# AT32F403xx register map
Vendor: Keil; Series: AT32F403; File version: 1.0
CPU: CM4 r0p1, little endian, no MPU, FPU, 4 interrupt priority bits
Registers are 32-bit, read-write, reset 0x0 unless marked. A register's access mark holds for its fields unless they carry their own. Offsets are from the block's base; [hi:lo] are bit positions; {n}, {i} and the like mark numbered series; 'fields as' and 'values as' point back to an identical list.

## AFIO — Alternate function I/O
Base 0x40010000
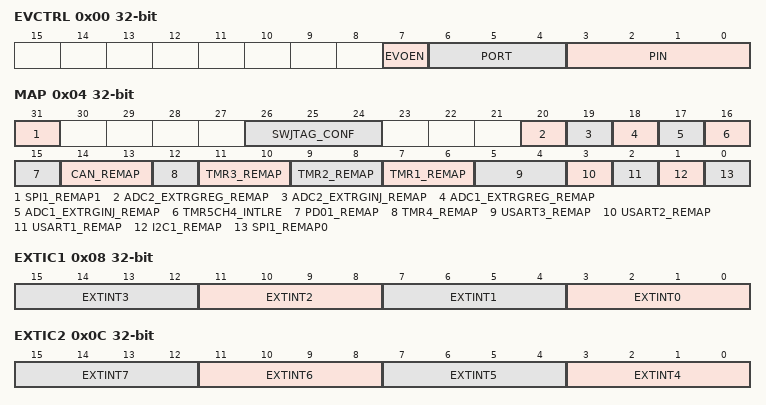
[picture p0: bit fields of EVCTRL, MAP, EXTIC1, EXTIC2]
0x00 EVCTRL — Event Control Register (AFIO_EVCTRL)
  [7] EVOEN — Event Output Enable
  [6:4] PORT — Port selection
  [3:0] PIN — Pin selection
0x04 MAP — AF remap and debug I/O configuration register (AFIO_MAP)
  [31] SPI1_REMAP1 — SPI1 remapping bit1
  [26:24] SWJTAG_CONF — Serial wire JTAG configuration
  [20] ADC2_EXTRGREG_REMAP — ADC 2 external trigger regular conversion remapping
  [19] ADC2_EXTRGINJ_REMAP — ADC 2 external trigger injected conversion remapping
  [18] ADC1_EXTRGREG_REMAP — ADC 1 external trigger regular conversion remapping
  [17] ADC1_EXTRGINJ_REMAP — ADC 1 External trigger injected conversion remapping
  [16] TMR5CH4_INTLRE — Set and cleared by software
  [15] PD01_REMAP — Port D0/Port D1 mapping on OSCIN/OSCOUT
  [14:13] CAN_REMAP — CAN1 remapping
  [12] TMR4_REMAP — TIM4 remapping
  [11:10] TMR3_REMAP — TIM3 remapping
  [9:8] TMR2_REMAP — TIM2 remapping
  [7:6] TMR1_REMAP — TIM1 remapping
  [5:4] USART3_REMAP — USART3 remapping
  [3] USART2_REMAP — USART2 remapping
  [2] USART1_REMAP — USART1 remapping
  [1] I2C1_REMAP — I2C1 remapping
  [0] SPI1_REMAP0 — SPI1 remapping bit0
0x08 EXTIC1 — External interrupt configuration register 1 (AFIO_EXTIC1)
  [4n+3:4n] EXTINT{n} (n=0..3) — EXTI{n} configuration
0x0C EXTIC2 — External interrupt configuration register 2 (AFIO_EXTIC2)
  [4n-13:4n-16] EXTINT{n} (n=4..7) — EXTI{n} configuration
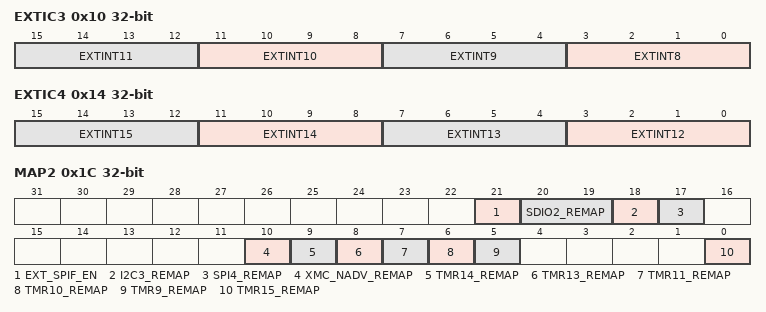
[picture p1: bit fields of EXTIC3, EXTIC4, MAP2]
0x10 EXTIC3 — External interrupt configuration register 3 (AFIO_EXTIC3)
  [4n-29:4n-32] EXTINT{n} (n=8..11) — EXTI{n} configuration
0x14 EXTIC4 — External interrupt configuration register 4 (AFIO_EXTIC4)
  [4n-45:4n-48] EXTINT{n} (n=12..15) — EXTI{n} configuration
0x1C MAP2 — AF remap and debug I/O configuration register
  [21] EXT_SPIF_EN — Enable ExtSPIFlash
  [20:19] SDIO2_REMAP — SDIO2 remapping
  [18] I2C3_REMAP — I2C3 remapping
  [17] SPI4_REMAP — SPI4 remapping
  [10] XMC_NADV_REMAP — NADV connect/disconnect
  [9] TMR14_REMAP — TIM14 remapping
  [8] TMR13_REMAP — TIM13 remapping
  [7] TMR11_REMAP — TIM11 remapping
  [6] TMR10_REMAP — TIM10 remapping
  [5] TMR9_REMAP — TIM9 remapping
  [0] TMR15_REMAP — TIM15 remapping

## EXTI
Base 0x40010400
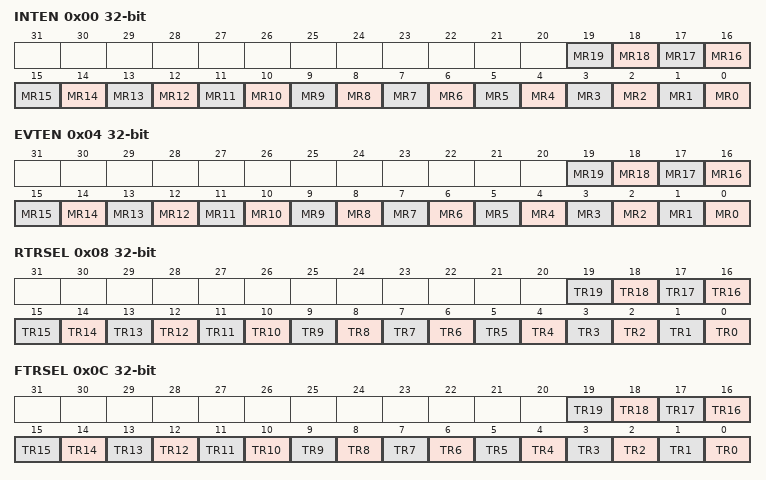
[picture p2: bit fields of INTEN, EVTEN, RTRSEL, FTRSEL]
0x00 INTEN — Interrupt mask register (EXTI_INTEN)
  [n] MR{n} (n=0..19) — Interrupt Mask on line {n}
0x04 EVTEN — Event mask register (EXTI_EVTEN)
  [n] MR{n} (n=0..19) — Event Mask on line {n}
0x08 RTRSEL — Rising Trigger selection register (EXTI_RTRSEL)
  [n] TR{n} (n=0..19) — Rising trigger event configuration of line {n}
0x0C FTRSEL — Falling Trigger selection register (EXTI_FTRSEL)
  [n] TR{n} (n=0..19) — Falling trigger event configuration of line {n}
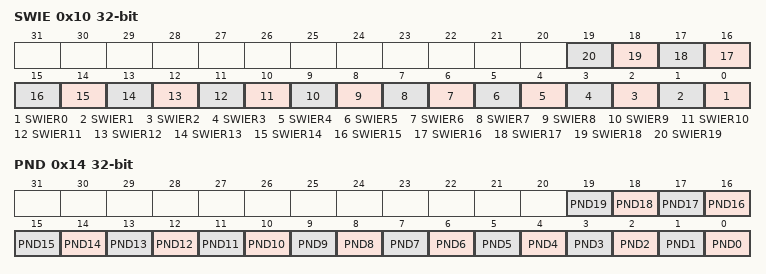
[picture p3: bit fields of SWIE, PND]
0x10 SWIE — Software interrupt event register (EXTI_SWIE)
  [n] SWIER{n} (n=0..19) — Software Interrupt on line {n}
0x14 PND — Pending register (EXTI_PND)
  [n] PND{n} (n=0..19) — Pending bit {n}

## DMA1 — DMA controller
Base 0x40020000
Same registers: DMA2 0x40020400
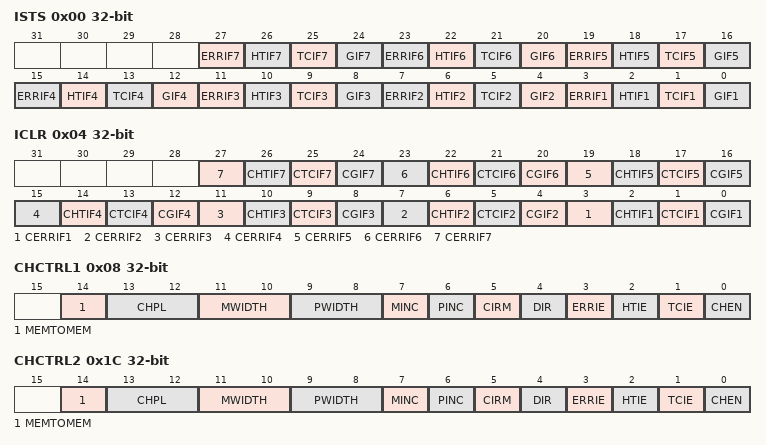
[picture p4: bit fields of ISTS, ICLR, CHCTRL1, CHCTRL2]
0x00 ISTS ro — DMA interrupt status register (DMA_ISTS)
  [4n-1] ERRIF{n} (n=1..7) — Channel {n} Transfer Error flag
  [4n-2] HTIF{n} (n=1..7) — Channel {n} Half Transfer Complete flag
  [4n-3] TCIF{n} (n=1..7) — Channel {n} Transfer Complete flag
  [4n-4] GIF{n} (n=1..7) — Channel {n} Global interrupt flag
0x04 ICLR — DMA interrupt flag clear register (DMA_ICLR)
  [4n-1] CERRIF{n} (n=1..7) — Channel {n} Transfer Error clear
  [4n-2] CHTIF{n} (n=1..7) — Channel {n} Half Transfer clear
  [4n-3] CTCIF{n} (n=1..7) — Channel {n} Transfer Complete clear
  [4n-4] CGIF{n} (n=1..7) — Channel {n} Global interrupt clear
0x08 CHCTRL1 — DMA channel configuration register (DMA_CCR)
  [14] MEMTOMEM — Memory to memory mode
  [13:12] CHPL — Channel Priority level
  [11:10] MWIDTH — Memory size
  [9:8] PWIDTH — Peripheral size
  [7] MINC — Memory increment mode
  [6] PINC — Peripheral increment mode
  [5] CIRM — Circular mode
  [4] DIR — Data transfer direction
  [3] ERRIE — Transfer error interrupt enable
  [2] HTIE — Half Transfer interrupt enable
  [1] TCIE — Transfer complete interrupt enable
  [0] CHEN — Channel enable
0x0C TCNT1 — DMA channel 1 number of data register
  [15:0] CNT — Number of data to transfer
0x10 CPBA1 — DMA channel 1 peripheral address register
  [31:0] PA — Peripheral address
{0x0+0x14*i} CMBA{i} (i=1..7) — DMA channel {i} memory address register
  [31:0] MA — Memory address
0x1C CHCTRL2 — DMA channel configuration register (DMA_CHCTRL2)
  fields as CHCTRL1
0x20 TCNT2 — DMA channel 2 number of data register
  [15:0] CNT — Number of data to transfer
0x24 CPBA2 — DMA channel 2 peripheral address register
  [31:0] PA — Peripheral address
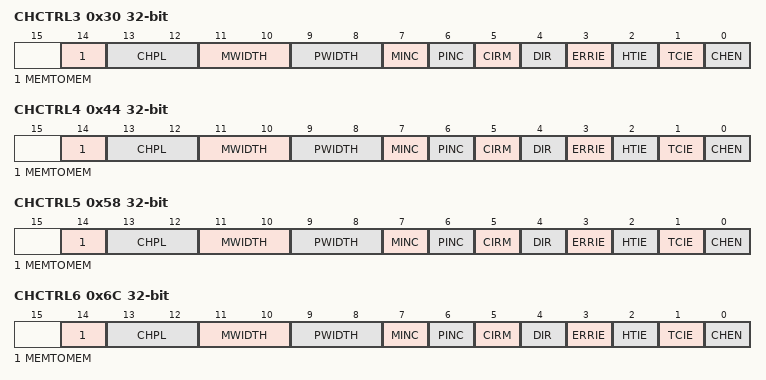
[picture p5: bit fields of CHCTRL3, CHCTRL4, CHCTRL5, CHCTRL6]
0x30 CHCTRL3 — DMA channel configuration register (DMA_CHCTRL3)
  fields as CHCTRL1
0x34 TCNT3 — DMA channel 3 number of data register
  [15:0] CNT — Number of data to transfer
0x38 CPBA3 — DMA channel 3 peripheral address register
  [31:0] PA — Peripheral address
0x44 CHCTRL4 — DMA channel configuration register (DMA_CHCTRL4)
  fields as CHCTRL1
0x48 TCNT4 — DMA channel 4 number of data register
  [15:0] CNT — Number of data to transfer
0x4C CPBA4 — DMA channel 4 peripheral address register
  [31:0] PA — Peripheral address
0x58 CHCTRL5 — DMA channel configuration register (DMA_CHCTRL5)
  fields as CHCTRL1
0x5C TCNT5 — DMA channel 5 number of data register
  [15:0] CNT — Number of data to transfer
0x60 CPBA5 — DMA channel 5 peripheral address register
  [31:0] PA — Peripheral address
0x6C CHCTRL6 — DMA channel configuration register (DMA_CHCTRL6)
  fields as CHCTRL1
0x70 TCNT6 — DMA channel 6 number of data register
  [15:0] CNT — Number of data to transfer
0x74 CPBA6 — DMA channel 6 peripheral address register
  [31:0] PA — Peripheral address
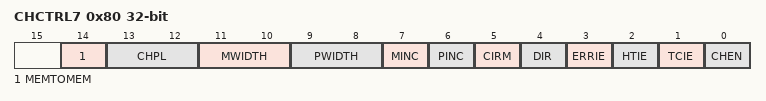
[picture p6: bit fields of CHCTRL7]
0x80 CHCTRL7 — DMA channel configuration register (DMA_CHCTRL7)
  fields as CHCTRL1
0x84 TCNT7 — DMA channel 7 number of data register
  [15:0] CNT — Number of data to transfer
0x88 CPBA7 — DMA channel 7 peripheral address register
  [31:0] PA — Peripheral address

## Notices in the file
Copyright (C) 2012-2014 ARM Limited. All rights reserved.
Purpose: System Viewer Description (SVD) Example (Schema Version 1.1)
This is a description of a none-existent and incomplete device
for demonstration purposes only.
Redistribution and use in source and binary forms, with or without
modification, are permitted provided that the following conditions are met:
- Redistributions of source code must retain the above copyright
notice, this list of conditions and the following disclaimer.
- Redistributions in binary form must reproduce the above copyright
notice, this list of conditions and the following disclaimer in the
documentation and/or other materials provided with the distribution.
- Neither the name of ARM nor the names of its contributors may be used
to endorse or promote products derived from this software without
specific prior written permission.
THIS SOFTWARE IS PROVIDED BY THE COPYRIGHT HOLDERS AND CONTRIBUTORS "AS IS"
AND ANY EXPRESS OR IMPLIED WARRANTIES, INCLUDING, BUT NOT LIMITED TO, THE
IMPLIED WARRANTIES OF MERCHANTABILITY AND FITNESS FOR A PARTICULAR PURPOSE
ARE DISCLAIMED. IN NO EVENT SHALL COPYRIGHT HOLDERS AND CONTRIBUTORS BE
LIABLE FOR ANY DIRECT, INDIRECT, INCIDENTAL, SPECIAL, EXEMPLARY, OR
CONSEQUENTIAL DAMAGES (INCLUDING, BUT NOT LIMITED TO, PROCUREMENT OF
SUBSTITUTE GOODS OR SERVICES; LOSS OF USE, DATA, OR PROFITS; OR BUSINESS
INTERRUPTION) HOWEVER CAUSED AND ON ANY THEORY OF LIABILITY, WHETHER IN
CONTRACT, STRICT LIABILITY, OR TORT (INCLUDING NEGLIGENCE OR OTHERWISE)
ARISING IN ANY WAY OUT OF THE USE OF THIS SOFTWARE, EVEN IF ADVISED OF THE
POSSIBILITY OF SUCH DAMAGE.
